# nrf9230_enga_application register map
Vendor: Nordic Semiconductor; Series: nRF92; File version: 1
CPU: CM33 r0p4, little endian, MPU, FPU, 3 interrupt priority bits, 480 interrupts, 4 SAU regions
Registers are 32-bit, read-write, reset 0x0 unless marked. A register's access mark holds for its fields unless they carry their own. Offsets are from the block's base; [hi:lo] are bit positions; lines under a group give offsets from that group; {n}, {i} and the like mark numbered series; 'fields as' and 'values as' point back to an identical list.

## GLOBAL_OTPC_S — OTP controller
Base 0x5F8C5000
0x100 EVENTS_READY — Current OTPC operation is completed.
  [0] EVENTS_READY
    0=NotGenerated (Event not generated); 1=Generated (Event generated)
0x104 EVENTS_READYNEXT — Ready to accept a new write operation.
  [0] EVENTS_READYNEXT
    values as EVENTS_READY.EVENTS_READY
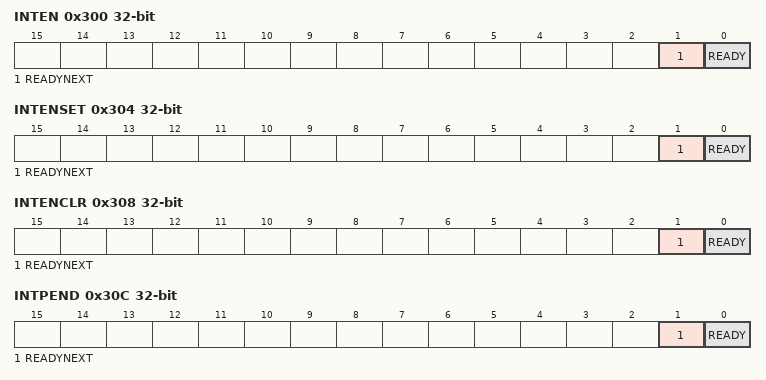
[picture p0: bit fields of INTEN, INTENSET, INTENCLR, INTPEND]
0x300 INTEN — Enable or disable interrupt
  [1] READYNEXT — Enable or disable interrupt for event READYNEXT
    0=Disabled; 1=Enabled
  [0] READY — Enable or disable interrupt for event READY
    0=Disabled; 1=Enabled
0x304 INTENSET — Enable interrupt
  [1] READYNEXT — Write '1' to enable interrupt for event READYNEXT
    on read: 0=Disabled (Read: Disabled); 1=Enabled (Read: Enabled) | on write: 1=Set (Enable)
  [0] READY — Write '1' to enable interrupt for event READY
    values as READYNEXT
0x308 INTENCLR — Disable interrupt
  [1] READYNEXT — Write '1' to disable interrupt for event READYNEXT
    on read: 0=Disabled (Read: Disabled); 1=Enabled (Read: Enabled) | on write: 1=Clear (Disable)
  [0] READY — Write '1' to disable interrupt for event READY
    values as READYNEXT
0x30C INTPEND ro — Pending interrupts
  [1] READYNEXT — Read pending status of interrupt for event READYNEXT
    on read: 0=NotPending (Read: Not pending); 1=Pending (Read: Pending)
  [0] READY — Read pending status of interrupt for event READY
    values as READYNEXT
0x400 READY ro reset 0x1 — OTPC status.
  [0] READY — The OTPC is ready or busy
    0=Busy (OTPC is busy.); 1=Ready (Current operation is completed and OTPC is ready.)
0x404 READYNEXT ro reset 0x1 — Ready next flag.
  [0] READYNEXT — OTPC can accept a new write operation.
    0=Busy (OTPC cannot accept any write operation.); 1=Ready (OTPC is ready to accept a new write operation.)
0x500 CONFIG — Configuration register.
  [0] WEN — When the write is enabled, the writes to OTP are allowed, otherwise the write is ignored. The OTP read is allowed regardless of WEN setting.
    0=DisableWrite (Write is disabled.); 1=EnableWrite (Write is enabled.)
0x520 POWER group — Unspecified
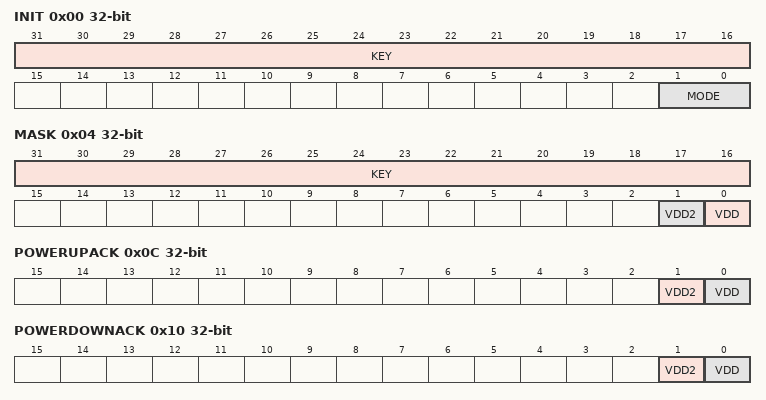
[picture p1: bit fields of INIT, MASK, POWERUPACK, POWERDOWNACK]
  0x00 INIT — Initiates power mode switching sequence.
    [31:16] KEY wo — Key to enable the writing to this register. Writes to this register are ignored if KEY is not set to 0xA66D.
      0xA66D=Allowed (Write is allowed.)
    [1:0] MODE — Switch power mode.
      0=PowerDown (Triggers power down sequence.); 1=PowerUp (Triggers power up sequence.)
  0x04 MASK — Mask for overriding of the various voltage supplies while switching power modes.
    [31:16] KEY wo — Key to enable the writing to this register. Writes to this register are ignored if KEY is not set to 0xA66D.
      0xA66D=Allowed (Write is allowed.)
    [1] VDD2 — Mask VDD2
      0=NoOperation; 1=Mask VDD2
    [0] VDD — Mask VDD
      0=NoOperation; 1=Mask VDD
  0x08 STATUS ro — Status on the power up/down sequence.
    [2:0] STATE — The current power up/down state.
      0=Off (OTP is OFF.); 1=PowerUpSeq (OTP power up sequence is active.); 2=Standby (OTP is in standby mode.); 3=Active (OTP is in active mode.); 4=PowerDownSeq (OTP power down sequence is active.)
  0x0C POWERUPACK ro — Status of the power control signals acknowledgment during power up sequence.
    [1] VDD2 — Waiting for VDD2 up ACK or not.
      0=NoOperation (Not waiting for VDD2 up ACK.); 1=Ack (Waiting for VDD2 up ACK)
    [0] VDD — Waiting for VDD up ACK or not.
      0=NoOperation (Not waiting for VDD up ACK.); 1=Ack (Waiting for VDD up ACK.)
  0x10 POWERDOWNACK ro — Status of the power control signals acknowledgment during power down sequence.
    [1] VDD2 — Waiting for VDD2 down ACK or not.
      0=NoOperation (Not waiting for VDD2 down ACK.); 1=Ack (Waiting for VDD2 down ACK.)
    [0] VDD — Waiting for VDD down ACK or not.
      0=NoOperation (Not waiting for VDD down ACK.); 1=Ack (Waiting for VDD down ACK.)
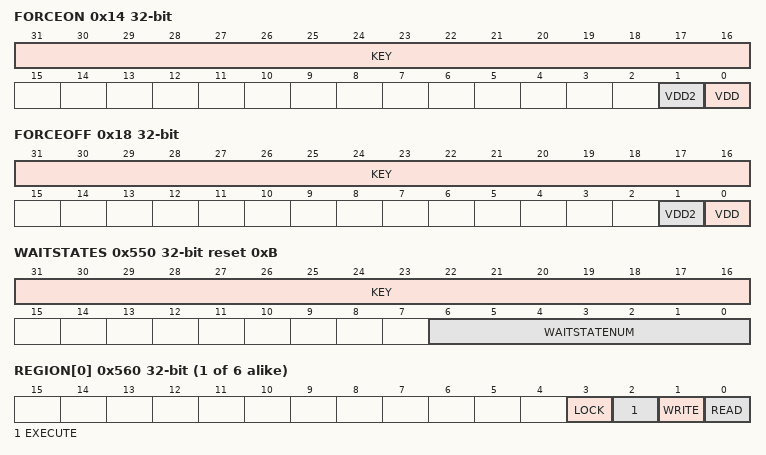
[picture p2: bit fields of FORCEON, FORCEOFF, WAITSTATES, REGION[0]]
  0x14 FORCEON — Force ON the power supply.
    [31:16] KEY wo — Key to enable the writing to this register. Writes to this register are ignored if KEY is not set to 0xA66D.
      0xA66D=Allowed (Write is allowed.)
    [1] VDD2 — Force ON the VDD2 supply.
      0=NoOperation (No Force ON.); 1=ForceOn
    [0] VDD — Force ON the VDD supply
      0=NoOperation (No Force ON.); 1=ForceOn
  0x18 FORCEOFF — Force OFF the power supply.
    [31:16] KEY wo — Key to enable the writing to this register. Writes to this register are ignored if KEY is not set to 0xA66D.
      0xA66D=Allowed (Write is allowed.)
    [1] VDD2 — Force OFF the VDD2 supply.
      0=NoOperation (No Force OFF.); 1=ForceOff
    [0] VDD — Force OFF the VDD supply
      0=NoOperation (No Force OFF.); 1=ForceOff
0x540 PUF group — Unspecified
  0x00 READ ro — Read the PUF word XORed with the PUF pad value.
    [31:0] Value — PUF word from the the PUF bits stream XORed with the PUF pad value.
      0=Locked (Reads a 0 when the PUF is locked.)
  0x04 PAD wo — The PUF pad value used to XOR with the PUF word read.
    [31:0] Value — PUF pad value
  0x08 LOCK — Locks the reads to the PUF.
    [31:0] LOCK — Enables the lock for PUF.READ.
      on read: 0=Pending (Read: The PUF.PAD is not written. The PUF.READ is locked.); 1=Disabled (Read: PUF.READ is not locked.); 2=Enabled (Read: PUF.READ is locked.) | on write: 0x10CC10CC=Enable (Write: Enables the lock (Ignores any other value written).)
0x550 WAITSTATES reset 0xB — Wait states for OTP read.
  [31:16] KEY wo — Key to enable the writing to this register. Writes to this register are ignored if KEY is not set to 0xA66D.
    0xA66D=Allowed (Write is allowed.)
  [6:0] WAITSTATENUM — Register to read the current number of wait states for the OTP read and to set a new value.
0x554 STANDBYTIMEOUT — Timeout to go into standby mode.
  [8:0] TIMEOUT — Timeout in terms of OTPC clock cycles, based on FREQUENCY.
0x558 FREQUENCY reset 0x64 — Clock frequency of OTPC.
  [9:0] FREQUENCY — Frequency in MHz.
{0x560+4i} REGION[{i}] (i=0..5) — Description collection: Configuration for region [n]
  [3] LOCK write-1-sets — Lock writes to this register.
    0=NotLocked (Register is not locked.); 1=Locked (Register is locked.)
  [2] EXECUTE write-1-sets — Code execute configuration to the region [n].
    0=Allowed (Code execute from the region [n] allowed.); 1=NotAllowed (Code execute from region [n] not allowed.)
  [1] WRITE write-1-sets — Write configuration to the region [n].
    0=Allowed (Writes to the region [n] allowed.); 1=NotAllowed (Writes to the region [n] not allowed.)
  [0] READ write-1-sets — Read configuration to the region [n].
    0=Allowed (Reads to the region [n] allowed.); 1=NotAllowed (Reads to the region [n] not allowed.)
0x600 TEST group — Unspecified
  0x00 TESTMODE — Register for entering test mode. Refer to the OTP test flow documentation for more details.
    [15:0] TESTMODE — Register for entering test mode. This register does not return the same value as written.
      on read: 0=NORMAL (Read: In normal mode.); 1=Read: In TESTMODE1 mode; 2=Read: In TESTMODE2 mode | on write: 0=SetNORMAL (Write: Sets NORMAL mode.); 0xBCDE=SetTESTMODE1 (Write: Sets TESTMODE1. Used for production tests.); 0xABCD=SetTESTMODE2 (Write: Sets TESTMODE2. Used for production tests (Direct access to OTP macro signals).)
  0x04 LOCKTESTMODE — Enables the lock for the TEST.TESTMODE
    [31:0] EnableLock — Enables the lock for TEST.TESTMODE.
      on read: 0=LockDisabled (Read: TEST.TESTMODE is not locked.); 1=LockEnabled (Read: TEST.TESTMODE is locked.) | on write: 0x10CC10CC=EnableLock (Write: Enables the lock (Ignores any other value written).)
0x610 TESTMODE1 group — Unspecified
  0x00 EMEMORY group — Unspecified
    0x00 READ — Configures the OTP memory read mode. The PTM signals of the OTP macro are set accordingly to this read mode during reads.
      [1:0] READ — OTP mempory read mode.
        0=Normal read mode; 1=PGM margin read mode; 2=Initial margin read mode
    0x04 PTR — Enables the PTR (PTR is the direct signal to the OTP macro, it enables the test row) for read or write. When enabled, the read and writes goes to test row instead of main OTP memory.
      [0] PTR — Enable PTR.
        0=Disable PTR; 1=Enable PTR
0x620 TESTMODE2 group — Unspecified
  0x00 EMEMORY group — Unspecified
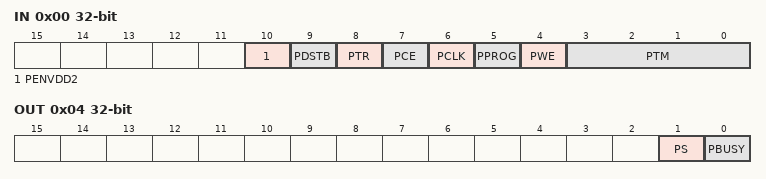
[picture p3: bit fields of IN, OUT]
    0x00 IN wo — Writes directly to the input signals of the OTP macro.
      [10] PENVDD2 — VDD2 enable pin (VDD2 domain).
      [9] PDSTB — Deep standby mode enabling.
      [8] PTR — Test row enable.
      [7] PCE — IP enabling.
      [6] PCLK — Clock input.
      [5] PPROG — Program Mode enabling.
      [4] PWE — Define program cycle.
      [3:0] PTM — Test mode enabling.
    0x04 OUT ro — Reads directly from the output signals of the OTP macro.
      [1] PS — Auto PUF margin read success.
      [0] PBUSY — Auto enrollment busy pin.
    0x08 PA wo — Writes directly to the address input PA of the OTP macro.
      [11:0] PA — Address input for read/write operation.
    0x0C PAIO wo — Writes directly to the address input PAIO of the OTP macro
      [5:0] PAIO — Address input for write operation.
    0x10 DATA reset 0xFFFFFFFF — OTP read/write data
      [31:0] DATA — OTP data register
  0x24 COUNTERCONFIG — Configuration register for the counter.
    [0] OPERATIONMODE — Enable counter-triggered latching of read data from OTP.
      0=Direct (The TESTMODE2.EMEMORY.DATA[31:0] register reads the direct value of PDOUT[31:0] of eMemory OTP.); 1=Latched (The TESTMODE2.EMEMORY.DATA register reads the latched value of PDOUT[31:0] of eMemory OTP.)
  0x28 COUNTERSTART wo — Starts the counter. Only applicable when TESTMODE2.COUNTERCONFIG.OPERATIONMODE = Direct.
    [0] TRIGGER — Start the counter.
      0=NoOperation; 1=Start the counter. Only applicable when TESTMODE2.COUNTERCONFIG.OPERATIONMODE=Direct.
  0x2C COUNTERRELOAD — Reload value for counter.
    [8:0] RELOAD — This is the counter reload value, used each time the decrementing counter is triggered.
  0x30 COUNTERRUN ro — Status of the counter.
    [0] RUNNING — Checks if counter is running.
      0=NotRunning (Counter is not running.); 1=Running (Counter is running.)
